# YTM32B1HA0 register map
Vendor: YTMicro; File version: 1.0
CPU: little endian, MPU, FPU, 2 interrupt priority bits
Registers are 32-bit, read-write, reset 0x0 unless marked. A register's access mark holds for its fields unless they carry their own. Offsets are from the block's base; [hi:lo] are bit positions; {n}, {i} and the like mark numbered series.

## EFM — Embedded FLASH Module
Base 0x40040000; register names take the prefix EFM_
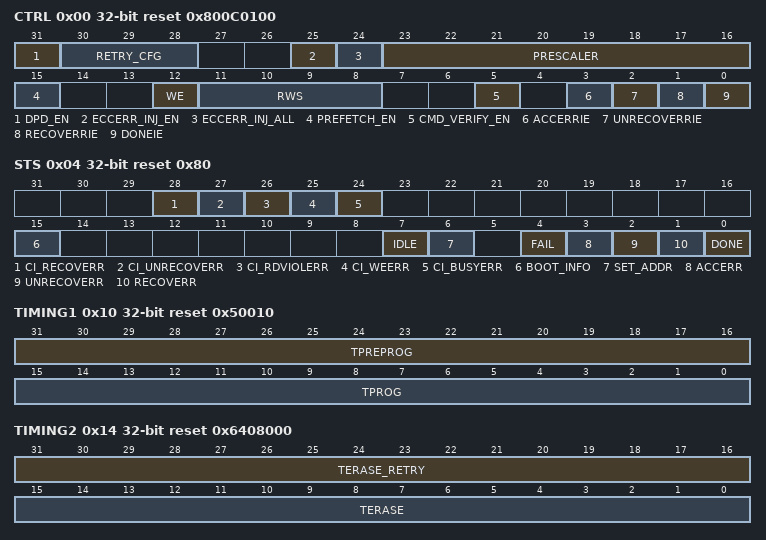
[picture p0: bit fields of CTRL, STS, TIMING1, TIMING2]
0x00 CTRL reset 0x800C0100
  [31] DPD_EN — This DPD_EN bit determines whether the Flash will enter deep power-down mode when MCU is entering deep sleep mode.
    0=Flash will keep active when MCU enters deep sleep mode; 1=Flash will enter deep power-down mode when MCU enters deep sleep mode
  [30:28] RETRY_CFG — These RETRY_CFG bits set Erase-Retry order in manual-erase operation. ewline For pre-erase control, RETRY_CFG[2:0] ewline =001 for 1st pre-erase pulse ewline =010 for 2nd pre-erase pulse ewline For Erase-Retry control, RETRY_CFG[2:0] ewline =100 for 1st erase pulse ewline =101 for 2nd erase pulse ewline =110 for 3rd erase pulse ewline =111 for4th to 20th erase pulse ewline
  [25] ECCERR_INJ_EN — This ECCERR_INJ_EN bit determines whether inject ECC error when Flash read.
    0=Disable ECC error inject when read Flash; 1=Enable ECC error inject when read Flash
  [24] ECCERR_INJ_ALL — This ECCERR_INJ_ALL bit determines ECC error inject happens for whether single or all Flash addresses.
    0=ECC error inject only when read address set in ECCERR_INJECT_ADDR[31:0]; 1=ECC error inject when read any Flash address
  [23:16] PRESCALER — These PRESCALER bits are used for EFM operation time control. ewline These bits need to be configured to half of APB clock frequency. ewline Please use the following equation to calculate the PRESCALER value: ewline PRESCALER = APB clock frequency / 2 (round up if not divisible). ewline Please re-configure PRESCALER once the frequency is changed.
  [15] PREFETCH_EN — This PREFETCH_EN bit is used to enable prefetch read function. EFM read Flash address+1 when the bus interface is free. Then if bus read address+1 happens, prefetch hit, Flash data is send without waiting Flash access time. Only Flash main array support prefetch read function, read of NVR array will ignore this register.
    0=Disable prefetch read function; 1=Enable prefetch read function
  [12] WE — This WE bit determines whether Flash is writable. Write Flash when WE=0 cause HRESP error and EFM_STATUS[CI_WEERR] flag is set at the same time.
    0=Disable Flash write; 1=Enable Flash write
  [11:8] RWS
  [5] CMD_VERIFY_EN — This CMD_VERIFY_EN bit determine whether do verify read after erase or program operation during executing a command. In verify read stage, read back and check Flash data of target sector. If Flash data checked failed, EFM_STATUS[FAIL] flag is set.
    0=Disable verify read after erase or program operation; 1=Enable verify read after erase or program operation
  [3] ACCERRIE — This ACCERRIE bit determines whether the interrupt will be generated if ACCERR flag is asserted.
    0=Disable generating interrupt if ACCERR flag is asserted; 1=Enable generating interrupt if ACCERR flag is asserted
  [2] UNRECOVERRIE — This UNRECOVERRIE bit determines whether the interrupt will be generated if UNRECOVERR flag is asserted.
    0=Disable generating interrupt if UNRECOVERR flag is asserted; 1=Enable generating interrupt if UNRECOVERR flag is asserted
  [1] RECOVERRIE — This RECOVERRIE bit determines whether the interrupt will be generated if RECOVERR flag is asserted.
    0=Disable generating interrupt if RECOVERR flag is asserted; 1=Enable generating interrupt if RECOVERR flag is asserted
  [0] DONEIE — This DONEIE bit determines whether the interrupt will be generated if DONE flag is asserted.
    0=Disable generating interrupt if DONE flag is asserted; 1=Enable generating interrupt if DONE flag is asserted
0x04 STS reset 0x80
  [28] CI_RECOVERR — 1-bit ECC error is detected during core read access cause HRESP error and set CI_RECOVERR flag.
    0=Recovery ecc error is not detected during core read access; 1=1-bit ECC error is detected during core read access
  [27] CI_UNRECOVERR — More than 2-bits ECC error is detected during core read access cause HRESP error and set CI_UNRECOVERR flag.
    0=No unrecovery ECC error during core read access; 1=2-bits ECC error or multi-bits ECC error is detected during core read access
  [26] CI_RDVIOLERR — This CI_RDVIOLERR bit indicates whether a read violation error is detected. ewline Read violation error includes below scenarios: ewline 1.Core read CUS_NVR sector when CUS_KEY is not set. ewline 2.Core read HCU_NVR sector when CFG_KEY is not set. ewline 3.Core read BOOT_NVR sector when FAC_KEY is not set. ewline 4.Core read FAC_NVR sector when FAC_KEY is not set. ewline 5.Core read NVR_CFG sectors when CFG_KEY is not set. ewline
  [25] CI_WEERR — The core tries to write Flash when EFM_CTRL[WE] is disabled cause HRESP error and set CI_WEERR flag.
  [24] CI_BUSYERR — The core tries to access Flash when EFM_CTRL[IDLE] is 0 cause HRESP error and set CI_BUSYERR flag.
  [15] BOOT_INFO ro — This BOOT_INFO bit indicates Flash loads codes from Block 0 or Block 1.
    0=Flash is loading codes from Block 0; 1=Flash is loading codes from Block 1
  [7] IDLE ro — This IDLE bit indicates whether Flash is busy. IDLE is 0 in bellow scenarios: ewline 1. EFM is executing a command. ewline 2. The core is reading NVR array(dummy read command).
  [6] SET_ADDR ro — A write access to target address is needed before sending a command. The write access operation will set SET_ADDR flag. ewline ote{Sending a command when SET_ADDR is 1 avoids ACCERR caused by code's non-sequential schedule on AXI and AHBP interface.}
  [4] FAIL — This FAIL bit indicates whether the current command is failed. ewline Command fail includes below scenarios: ewline 1.program verify check is failed. ewline 2.erase verify check is failed. ewline 3.Manual Erase-Retry Verify_Read check failed
  [3] ACCERR — This ACCERR bit indicates whether there is an access error is detected. ewline Access error scenarios refer to chapter "Flash Illegal Operation".
    0=Access error is not detected; 1=Access error is detected
  [2] UNRECOVERR — This UNRECOVERR bit indicates whether more than 2-bit ECC error is detected during command verify read stage.
    0=No un-recovery ECC error is detected in command verify read stage; 1=2-bit or multi-bit ECC error find in command verify read stage
  [1] RECOVERR — This RECOVERR bit indicates whether there is a recovery ecc error is detected during command verify read stage.
    0=No recovery ECC error is detected in command verify read stage; 1=1-bit ECC error is detected in command verify read stage
  [0] DONE — This DONE bit indicates whether the current command is completed.
    0=Current command is in progress; 1=Current command is completed
0x08 CMD
  [7:0] CMD — These CMD bits determine which commands are available.
    1=PROG64 ewline Program 64bits. Verify if CMD_VERIFY_EN is set 1.; 2=PROG256 ewline Program 256bits. Verify if CMD_VERIFY_EN is set 1.; 16=ERASE_SECTOR ewline Erase Sector. Verify if CMD_VERIFY_EN is set 1.; 17=ERASE_BLOCK ewline Erase Block (only main array). Verify if CMD_VERIFY_EN is set 1.; 18=ERASE_CHIP ewline Erase Chip (all main arrays and PFlash0's NVR array). Ignore CMD_VERIFY_EN.; 19=ERASE_RETRY_AUTO ewline Auto Erase-Retry (only main array sector); 20=ERASE_RETRY_MAN ewline Manual Erase-Retry (only main array sector); 21=ERASE_RETRY_VREAD ewline Manual Erase-Retry Verify-Read. Executed after a ERASE_RETRY_MAN command.; 32=LOAD_AES_KEY ewline Load AES Key command. Load 256-bits key data from Flash HCU_NVR array to HCU module.; 48=BOOT_SWAP ewline Boot Swap command to re-map block address
0x0C CMD_PROT
  [9:0] CMD_PROT — These CMD_PROT bits determine which commands are disabled. ewline Software can write 1 to value 0 bit, but can not clear value 1 bit to 0. ewline CMD_PROT[0]=1 disable PROG64 command; ewline CMD_PROT[1]=1 disable PROG256 command; ewline CMD_PROT[2]=1 disable ERASE_SECTOR command; ewline CMD_PROT[3]=1 disable Erase Block command; ewline CMD_PROT[4]=1 disable ERASE_CHIP command; ewline CMD_PROT[5]=1 disable ERASE_RETRY_AUTO command; ewline CMD_PROT[6]=1 disable ERASE_RETRY_MAN command; ewline CMD_PROT[7]=1 disable ERASE_RETRY_VREAD command; ewline CMD_PROT[8]=1 disable LOAD_AES_KEY command; ewline CMD_PROT[9]=1 disable BOOT_SWAP command;
0x10 TIMING1 reset 0x50010
  [31:16] TPREPROG — These TPREPROG bits indicate the pre-program time, and the time unit is 0.5us. ewline Please use the following equation to calculate TPREPROG value: ewline TPREPROG = (2.5 to 3.5) * 2
  [15:0] TPROG — These TPROG bits indicate the program time, and the time unit is 0.5us. ewline Please use the following equation to calculate TPROG value: ewline TPROG = (8 to 10) * 2
0x14 TIMING2 reset 0x6408000
  [31:16] TERASE_RETRY — These TERASE_RETRY bits indicate the Erase-Retry time, and the time unit is 0.5us. ewline Please use the following equation to calculate TERASE_RETRY value: ewline TERASE = (0.8 to 1) * 1000 * 2 ewline ote{Both Manual and Auto Erase-Retry are sector erase for main array.}
  [15:0] TERASE — These TERASE bits indicate the single erase time, and the time unit is 0.5us. ewline Please use the following equation to calculate TERASE value: ewline TERASE = (16 to 20) * 1000 * 2 ewline ote{Both ERASE_SECTOR and ERASE_CHIP command use this single erase time.}
0x18 ECCERR_INJECT_MSK_0
  [31:0] ECCERR_INJECT_MSK — ECCERR_INJECT_MSK[63:0] is used to inject ECC error into Flash read data bus (64 bits). ewline This field defines a bit-mapped mask that specifies whether the corresponding bit of the read data[31:0] from the target Flash should be inverted or remain unmodified. ewline For example, 32'h00000100 means Flash read data bit[12] is inverted. ewline This register is valid only when ECCERR_INJ_EN is 1.
0x1C ECCERR_INJECT_MSK_1
  [31:0] ECCERR_INJECT_MSK — This field defines a bit-mapped mask that specifies whether the corresponding bit of the read data[63:32] from the target Flash should be inverted or remain unmodified. ewline For example, 32'h00000002 means Flash read data bit[33] is inverted. ewline This register is valid only when ECCERR_INJ_EN is 1.
0x20 ECCERR_INJECT_ADDR
  [31:0] ECCERR_INJECT_ADDR — This field defines Flash address which to inject ECC error. This register is valid only when ECCERR_INJ_ALL is 0 and ECCERR_INJ_EN is 1. ewline
{0x24+4i} ADDR_PROT{i} reset 0xFFFFFFFF (i=0..2)
  [31:0] BLOCK_ADDR_PROT — Each bit protects 32 KByte PFlash address area. ewline If any bit is set to 0, the corresponding 32 KByte area is under protection (this Flash area is read only). ewline During initialization, EFM load the 2nd data of CUS_NVR to ADDR_PROT if it is programmed with right tag. ewline Software can write 0 to value 1 bit, but can not write 1 to value 0 bit.
0x30 ECC_ERR_ADDR reset 0xFFFFFFFF
  [31:0] ECC_ERR_ADDR — These bits recorded the first detected ECC error address. Followed ECC error address are not recorded. ewline When detect a ECC error, hardware set ECC error flag (CI_RECOVERR or CI_UNRECOVERR or RECOVERR or UNRECOVERRR). If ECC_ERR_ADDR is currently default, write error address to ECC_ERR_ADDR at the same time. ewline ECC_ERR_ADDR is cleared by write 1 to the corresponding error flag. If ECC_ERR_ADDR records CI_UNRECOVERR address, write 1 to CI_RECOVERR or RECOVERR or UNRECOVERRR could not clear ECC_ERR_ADDR.
0x200 CMD_UNLOCK
  [31:0] CMD_UNLOCK_KEY wo — Please write 0xfd9573f5 before launching any command
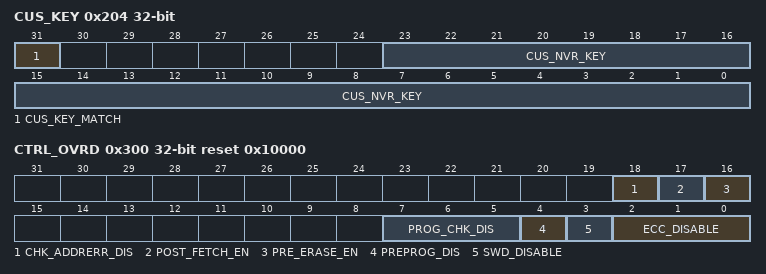
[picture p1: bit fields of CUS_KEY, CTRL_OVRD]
0x204 CUS_KEY
  [31] CUS_KEY_MATCH ro — This CUS_KEY_MATCH bit indicates whether Customer Key is matched.
    0=Customer Key is not matched; 1=Customer Key is matched
  [23:0] CUS_NVR_KEY wo — Please write Customer Key before any protected NVR operation. Default Customer Key is 0x4dff32, re-defined by program CUS NVR first address and reset EFM.
0x300 CTRL_OVRD reset 0x10000
  [18] CHK_ADDRERR_DIS — Check address error includes below scenarios: ewline 1. Not equal HADDR[31:5] of multiple bus write before sending a program 256bit command cause ACCERR. ewline 2. Not equal HADDR[31:3] of multiple bus write before sending a program 64bit command cause ACCERR.
    0=Check address error before program operation; 1=Don't check address error before program operation
  [17] POST_FETCH_EN — This bit determines whether bus read assist post-fetch function.
    0=Disable post-fetch function; 1=Enable post-fetch function
  [16] PRE_ERASE_EN — This bit determines whether do pre-erase in Auto Erase-Retry command.
  [7:5] PROG_CHK_DIS — Before program operation, read Flash and check if program target addresses are erased. This function called program check. ewline PRE_ERASE_EN[0] determine if PFlash0 program check is override disabled; ewline PRE_ERASE_EN[1] determine if PFlash1 program check is override disabled; ewline PRE_ERASE_EN[2] determine if DFlash program check is override disabled.
  [4] PREPROG_DIS — This bit determines whether do pre-program in program command.
  [3] SWD_DISABLE — This bit determines whether the Software Debugger is override disabled.
    0=Software Debugger is not override disabled; 1=Software Debugger is override disabled
  [2:0] ECC_DISABLE — ECC_DISABLE[0] determine if PFlash0 ECC is is override disabled; ewline ECC_DISABLE[1] determine if PFlash1 ECC is is override disabled; ewline ECC_DISABLE[2] determine if DFlash ECC is is override disabled.
